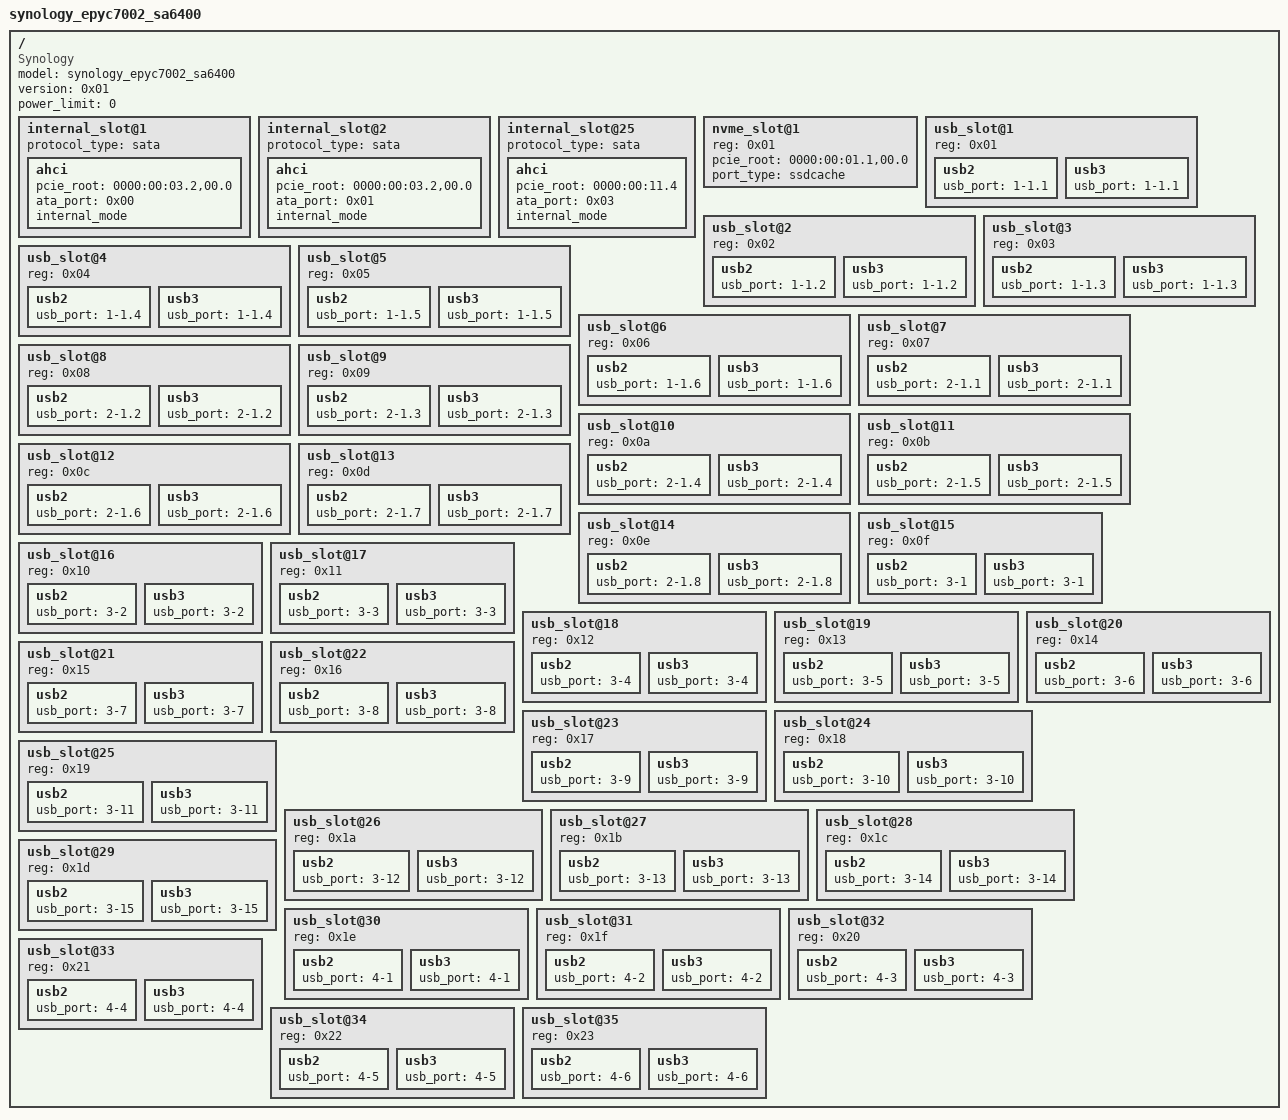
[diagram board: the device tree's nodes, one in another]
/dts-v1/;

/ {
	compatible = "Synology";
	model = "synology_epyc7002_sa6400";
	version = <0x01>;
	#address-cells = <0x01>;
	#size-cells = <0x00>;
	power_limit = "0";

	internal_slot@1 {
		protocol_type = "sata";

		ahci {
			pcie_root = "0000:00:03.2,00.0";
			ata_port = <0x00>;
			internal_mode;
		};
	};

	internal_slot@2 {
		protocol_type = "sata";

		ahci {
			pcie_root = "0000:00:03.2,00.0";
			ata_port = <0x01>;
			internal_mode;
		};
	};

	internal_slot@25 {
		protocol_type = "sata";

		ahci {
			pcie_root = "0000:00:11.4";
			ata_port = <0x03>;
			internal_mode;
		};
	};

	nvme_slot@1 {
		reg = <0x01>;
		pcie_root = "0000:00:01.1,00.0";
		port_type = "ssdcache";
	};

	usb_slot@1 {
		reg = <0x01>;

		usb2 {
			usb_port = "1-1.1";
		};

		usb3 {
			usb_port = "1-1.1";
		};
	};

	usb_slot@2 {
		reg = <0x02>;

		usb2 {
			usb_port = "1-1.2";
		};

		usb3 {
			usb_port = "1-1.2";
		};
	};

	usb_slot@3 {
		reg = <0x03>;

		usb2 {
			usb_port = "1-1.3";
		};

		usb3 {
			usb_port = "1-1.3";
		};
	};

	usb_slot@4 {
		reg = <0x04>;

		usb2 {
			usb_port = "1-1.4";
		};

		usb3 {
			usb_port = "1-1.4";
		};
	};

	usb_slot@5 {
		reg = <0x05>;

		usb2 {
			usb_port = "1-1.5";
		};

		usb3 {
			usb_port = "1-1.5";
		};
	};

	usb_slot@6 {
		reg = <0x06>;

		usb2 {
			usb_port = "1-1.6";
		};

		usb3 {
			usb_port = "1-1.6";
		};
	};

	usb_slot@7 {
		reg = <0x07>;

		usb2 {
			usb_port = "2-1.1";
		};

		usb3 {
			usb_port = "2-1.1";
		};
	};

	usb_slot@8 {
		reg = <0x08>;

		usb2 {
			usb_port = "2-1.2";
		};

		usb3 {
			usb_port = "2-1.2";
		};
	};

	usb_slot@9 {
		reg = <0x09>;

		usb2 {
			usb_port = "2-1.3";
		};

		usb3 {
			usb_port = "2-1.3";
		};
	};

	usb_slot@10 {
		reg = <0x0a>;

		usb2 {
			usb_port = "2-1.4";
		};

		usb3 {
			usb_port = "2-1.4";
		};
	};

	usb_slot@11 {
		reg = <0x0b>;

		usb2 {
			usb_port = "2-1.5";
		};

		usb3 {
			usb_port = "2-1.5";
		};
	};

	usb_slot@12 {
		reg = <0x0c>;

		usb2 {
			usb_port = "2-1.6";
		};

		usb3 {
			usb_port = "2-1.6";
		};
	};

	usb_slot@13 {
		reg = <0x0d>;

		usb2 {
			usb_port = "2-1.7";
		};

		usb3 {
			usb_port = "2-1.7";
		};
	};

	usb_slot@14 {
		reg = <0x0e>;

		usb2 {
			usb_port = "2-1.8";
		};

		usb3 {
			usb_port = "2-1.8";
		};
	};

	usb_slot@15 {
		reg = <0x0f>;

		usb2 {
			usb_port = "3-1";
		};

		usb3 {
			usb_port = "3-1";
		};
	};

	usb_slot@16 {
		reg = <0x10>;

		usb2 {
			usb_port = "3-2";
		};

		usb3 {
			usb_port = "3-2";
		};
	};

	usb_slot@17 {
		reg = <0x11>;

		usb2 {
			usb_port = "3-3";
		};

		usb3 {
			usb_port = "3-3";
		};
	};

	usb_slot@18 {
		reg = <0x12>;

		usb2 {
			usb_port = "3-4";
		};

		usb3 {
			usb_port = "3-4";
		};
	};

	usb_slot@19 {
		reg = <0x13>;

		usb2 {
			usb_port = "3-5";
		};

		usb3 {
			usb_port = "3-5";
		};
	};

	usb_slot@20 {
		reg = <0x14>;

		usb2 {
			usb_port = "3-6";
		};

		usb3 {
			usb_port = "3-6";
		};
	};

	usb_slot@21 {
		reg = <0x15>;

		usb2 {
			usb_port = "3-7";
		};

		usb3 {
			usb_port = "3-7";
		};
	};

	usb_slot@22 {
		reg = <0x16>;

		usb2 {
			usb_port = "3-8";
		};

		usb3 {
			usb_port = "3-8";
		};
	};

	usb_slot@23 {
		reg = <0x17>;

		usb2 {
			usb_port = "3-9";
		};

		usb3 {
			usb_port = "3-9";
		};
	};

	usb_slot@24 {
		reg = <0x18>;

		usb2 {
			usb_port = "3-10";
		};

		usb3 {
			usb_port = "3-10";
		};
	};

	usb_slot@25 {
		reg = <0x19>;

		usb2 {
			usb_port = "3-11";
		};

		usb3 {
			usb_port = "3-11";
		};
	};

	usb_slot@26 {
		reg = <0x1a>;

		usb2 {
			usb_port = "3-12";
		};

		usb3 {
			usb_port = "3-12";
		};
	};

	usb_slot@27 {
		reg = <0x1b>;

		usb2 {
			usb_port = "3-13";
		};

		usb3 {
			usb_port = "3-13";
		};
	};

	usb_slot@28 {
		reg = <0x1c>;

		usb2 {
			usb_port = "3-14";
		};

		usb3 {
			usb_port = "3-14";
		};
	};

	usb_slot@29 {
		reg = <0x1d>;

		usb2 {
			usb_port = "3-15";
		};

		usb3 {
			usb_port = "3-15";
		};
	};

	usb_slot@30 {
		reg = <0x1e>;

		usb2 {
			usb_port = "4-1";
		};

		usb3 {
			usb_port = "4-1";
		};
	};

	usb_slot@31 {
		reg = <0x1f>;

		usb2 {
			usb_port = "4-2";
		};

		usb3 {
			usb_port = "4-2";
		};
	};

	usb_slot@32 {
		reg = <0x20>;

		usb2 {
			usb_port = "4-3";
		};

		usb3 {
			usb_port = "4-3";
		};
	};

	usb_slot@33 {
		reg = <0x21>;

		usb2 {
			usb_port = "4-4";
		};

		usb3 {
			usb_port = "4-4";
		};
	};

	usb_slot@34 {
		reg = <0x22>;

		usb2 {
			usb_port = "4-5";
		};

		usb3 {
			usb_port = "4-5";
		};
	};

	usb_slot@35 {
		reg = <0x23>;

		usb2 {
			usb_port = "4-6";
		};

		usb3 {
			usb_port = "4-6";
		};
	};
};
